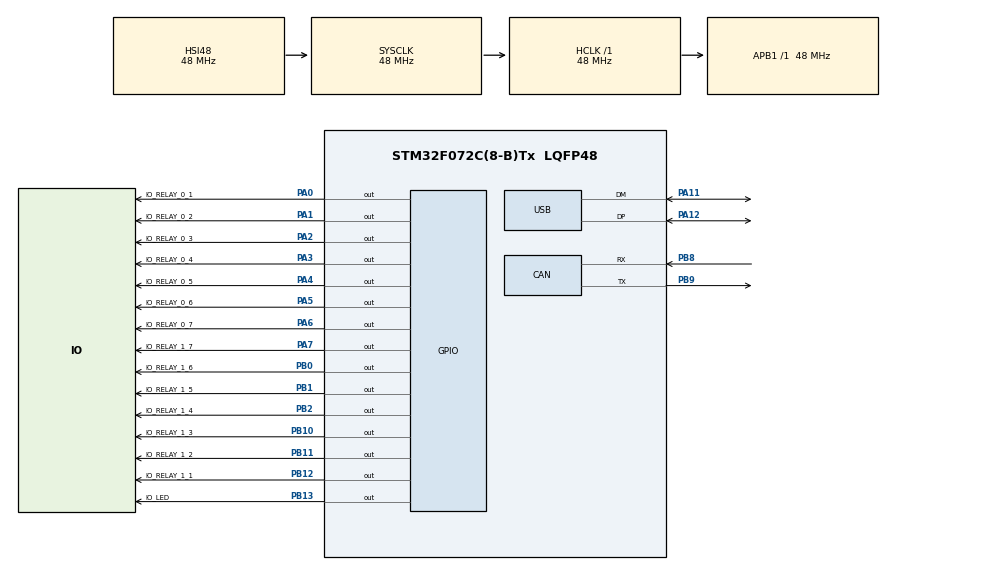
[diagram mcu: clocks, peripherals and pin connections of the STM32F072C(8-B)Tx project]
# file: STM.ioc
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CAN.CalculateTimeQuantum=333.3333333333333
FREERTOS.Queues01=cdcData,128,uint8_t,0,Dynamic,NULL,NULL
FREERTOS.Tasks01=ledToggleTask,-1,128,ledToggleTaskFunc,Default,NULL,Dynamic,NULL,NULL;uartTask,0,128,uartTaskFunc,Default,NULL,Dynamic,NULL,NULL
Mcu.Family=STM32F0
Mcu.Name=STM32F072C(8-B)Tx
Mcu.Package=LQFP48
NVIC.TIM1_BRK_UP_TRG_COM_IRQn=true\:0\:0\:false\:false\:true\:false\:false
NVIC.TimeBase=TIM1_BRK_UP_TRG_COM_IRQn
NVIC.TimeBaseIP=TIM1
NVIC.USB_IRQn=true\:3\:0\:false\:false\:true\:true\:false
PA0.GPIO_Label=IO_RELAY_0_1
PA0.Signal=GPIO_Output
PA1.GPIO_Label=IO_RELAY_0_2
PA1.Signal=GPIO_Output
PA11.Mode=Device
PA11.Signal=USB_DM
PA12.Mode=Device
PA12.Signal=USB_DP
PA2.GPIO_Label=IO_RELAY_0_3
PA2.Signal=GPIO_Output
PA3.GPIO_Label=IO_RELAY_0_4
PA3.Signal=GPIO_Output
PA4.GPIO_Label=IO_RELAY_0_5
PA4.Signal=GPIO_Output
PA5.GPIO_Label=IO_RELAY_0_6
PA5.Signal=GPIO_Output
PA6.GPIO_Label=IO_RELAY_0_7
PA6.Signal=GPIO_Output
PA7.GPIO_Label=IO_RELAY_1_7
PA7.Signal=GPIO_Output
PB0.GPIO_Label=IO_RELAY_1_6
PB0.Signal=GPIO_Output
PB1.GPIO_Label=IO_RELAY_1_5
PB1.Signal=GPIO_Output
PB10.GPIO_Label=IO_RELAY_1_3
PB10.Signal=GPIO_Output
PB11.GPIO_Label=IO_RELAY_1_2
PB11.Signal=GPIO_Output
PB12.GPIO_Label=IO_RELAY_1_1
PB12.Signal=GPIO_Output
PB13.GPIO_Label=IO_LED
PB13.Signal=GPIO_Output
PB2.GPIO_Label=IO_RELAY_1_4
PB2.Signal=GPIO_Output
PB3.Signal=SPI1_SCK
PB4.Signal=SPI1_MISO
PB5.Signal=SPI1_MOSI
PB8.Mode=Master
PB8.Signal=CAN_RX
PB9.Mode=Master
PB9.Signal=CAN_TX
ProjectManager.HeapSize=0x200
ProjectManager.StackSize=0x400
ProjectManager.TargetToolchain=TrueSTUDIO
RCC.AHBFreq_Value=48000000
RCC.APB1Freq_Value=48000000
RCC.APB1TimFreq_Value=48000000
RCC.HCLKFreq_Value=48000000
RCC.SYSCLKFreq_VALUE=48000000
RCC.SYSCLKSource=RCC_SYSCLKSOURCE_HSI48
USB_DEVICE.CLASS_NAME_FS=CDC
USB_DEVICE.VirtualMode=Cdc
USB_DEVICE.VirtualModeFS=Cdc_FS
VP_FREERTOS_VS_ENABLE.Mode=Enabled
VP_SYS_VS_tim1.Mode=TIM1
VP_USB_DEVICE_VS_USB_DEVICE_CDC_FS.Mode=CDC_FS
board=custom

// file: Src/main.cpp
/* USER CODE BEGIN Header */
/**
  ******************************************************************************
  * @file           : main.c
  * @brief          : Main program body
  ******************************************************************************
  ** This notice applies to any and all portions of this file
  * that are not between comment pairs USER CODE BEGIN and
  * USER CODE END. Other portions of this file, whether
  * inserted by the user or by software development tools
  * are owned by their respective copyright owners.
  *
  * COPYRIGHT(c) 2019 STMicroelectronics
  *
  * Redistribution and use in source and binary forms, with or without modification,
  * are permitted provided that the following conditions are met:
  *   1. Redistributions of source code must retain the above copyright notice,
  *      this list of conditions and the following disclaimer.
  *   2. Redistributions in binary form must reproduce the above copyright notice,
  *      this list of conditions and the following disclaimer in the documentation
  *      and/or other materials provided with the distribution.
  *   3. Neither the name of STMicroelectronics nor the names of its contributors
  *      may be used to endorse or promote products derived from this software
  *      without specific prior written permission.
  *
  * THIS SOFTWARE IS PROVIDED BY THE COPYRIGHT HOLDERS AND CONTRIBUTORS "AS IS"
  * AND ANY EXPRESS OR IMPLIED WARRANTIES, INCLUDING, BUT NOT LIMITED TO, THE
  * IMPLIED WARRANTIES OF MERCHANTABILITY AND FITNESS FOR A PARTICULAR PURPOSE ARE
  * DISCLAIMED. IN NO EVENT SHALL THE COPYRIGHT HOLDER OR CONTRIBUTORS BE LIABLE
  * FOR ANY DIRECT, INDIRECT, INCIDENTAL, SPECIAL, EXEMPLARY, OR CONSEQUENTIAL
  * DAMAGES (INCLUDING, BUT NOT LIMITED TO, PROCUREMENT OF SUBSTITUTE GOODS OR
  * SERVICES; LOSS OF USE, DATA, OR PROFITS; OR BUSINESS INTERRUPTION) HOWEVER
  * CAUSED AND ON ANY THEORY OF LIABILITY, WHETHER IN CONTRACT, STRICT LIABILITY,
  * OR TORT (INCLUDING NEGLIGENCE OR OTHERWISE) ARISING IN ANY WAY OUT OF THE USE
  * OF THIS SOFTWARE, EVEN IF ADVISED OF THE POSSIBILITY OF SUCH DAMAGE.
  *
  ******************************************************************************
  */
/* USER CODE END Header */

#include "main.h"
#include "cmsis_os.h"
#include "usb_device.h"

/* USER CODE BEGIN Includes */
#include "control.hpp"
/* USER CODE END Includes */

CAN_HandleTypeDef hcan;

osThreadId ledToggleTaskHandle;
osThreadId uartTaskHandle;
osMessageQId cdcDataHandle;

void SystemClock_Config(void);
static void MX_GPIO_Init(void);
static void MX_CAN_Init(void);
void ledToggleTaskFunc(void const * argument);
void uartTaskFunc(void const * argument);

int main(void)
{

  /* MCU Configuration--------------------------------------------------------*/

  /* Reset of all peripherals, Initializes the Flash interface and the Systick. */
  HAL_Init();

  /* Configure the system clock */
  SystemClock_Config();

  /* Initialize all configured peripherals */
  MX_GPIO_Init();
  MX_CAN_Init();

  /* Create the thread(s) */
  /* definition and creation of ledToggleTask */
  osThreadDef(ledToggleTask, ledToggleTaskFunc, osPriorityBelowNormal, 0, 128);
  ledToggleTaskHandle = osThreadCreate(osThread(ledToggleTask), NULL);

  /* definition and creation of uartTask */
  osThreadDef(uartTask, uartTaskFunc, osPriorityNormal, 0, 128);
  uartTaskHandle = osThreadCreate(osThread(uartTask), NULL);

  /* Create the queue(s) */
  /* definition and creation of cdcData */
  osMessageQDef(cdcData, 128, uint8_t);
  cdcDataHandle = osMessageCreate(osMessageQ(cdcData), NULL);

  /* Start scheduler */
  osKernelStart();

  /* We should never get here as control is now taken by the scheduler */

  /* Infinite loop */
  while (1)
  {

  }
}

void SystemClock_Config(void)
{
  RCC_OscInitTypeDef RCC_OscInitStruct = {0};
  RCC_ClkInitTypeDef RCC_ClkInitStruct = {0};
  RCC_PeriphCLKInitTypeDef PeriphClkInit = {0};

  /**Initializes the CPU, AHB and APB busses clocks
  */
  RCC_OscInitStruct.OscillatorType = RCC_OSCILLATORTYPE_HSI48;
  RCC_OscInitStruct.HSI48State = RCC_HSI48_ON;
  RCC_OscInitStruct.PLL.PLLState = RCC_PLL_NONE;
  if (HAL_RCC_OscConfig(&RCC_OscInitStruct) != HAL_OK)
  {
    Error_Handler();
  }
  /**Initializes the CPU, AHB and APB busses clocks
  */
  RCC_ClkInitStruct.ClockType = RCC_CLOCKTYPE_HCLK|RCC_CLOCKTYPE_SYSCLK
                              |RCC_CLOCKTYPE_PCLK1;
  RCC_ClkInitStruct.SYSCLKSource = RCC_SYSCLKSOURCE_HSI48;
  RCC_ClkInitStruct.AHBCLKDivider = RCC_SYSCLK_DIV1;
  RCC_ClkInitStruct.APB1CLKDivider = RCC_HCLK_DIV1;

  if (HAL_RCC_ClockConfig(&RCC_ClkInitStruct, FLASH_LATENCY_1) != HAL_OK)
  {
    Error_Handler();
  }
  PeriphClkInit.PeriphClockSelection = RCC_PERIPHCLK_USB;
  PeriphClkInit.UsbClockSelection = RCC_USBCLKSOURCE_HSI48;

  if (HAL_RCCEx_PeriphCLKConfig(&PeriphClkInit) != HAL_OK)
  {
    Error_Handler();
  }
}

static void MX_CAN_Init(void)
{

  hcan.Instance = CAN;
  hcan.Init.Prescaler = 16;
  hcan.Init.Mode = CAN_MODE_NORMAL;
  hcan.Init.SJW = CAN_SJW_1TQ;
  hcan.Init.BS1 = CAN_BS1_1TQ;
  hcan.Init.BS2 = CAN_BS2_1TQ;
  hcan.Init.TTCM = DISABLE;
  hcan.Init.ABOM = DISABLE;
  hcan.Init.AWUM = DISABLE;
  hcan.Init.NART = DISABLE;
  hcan.Init.RFLM = DISABLE;
  hcan.Init.TXFP = DISABLE;
  if (HAL_CAN_Init(&hcan) != HAL_OK)
  {
    Error_Handler();
  }

}

static void MX_GPIO_Init(void)
{
  GPIO_InitTypeDef GPIO_InitStruct = {0};

  /* GPIO Ports Clock Enable */
  __HAL_RCC_GPIOA_CLK_ENABLE();
  __HAL_RCC_GPIOB_CLK_ENABLE();

  /*Configure GPIO pin Output Level */
  HAL_GPIO_WritePin(GPIOA, IO_RELAY_0_1_Pin|IO_RELAY_0_2_Pin|IO_RELAY_0_3_Pin|IO_RELAY_0_4_Pin
                          |IO_RELAY_0_5_Pin|IO_RELAY_0_6_Pin|IO_RELAY_0_7_Pin|IO_RELAY_1_7_Pin, GPIO_PIN_RESET);

  /*Configure GPIO pin Output Level */
  HAL_GPIO_WritePin(GPIOB, IO_RELAY_1_6_Pin|IO_RELAY_1_5_Pin|IO_RELAY_1_4_Pin|IO_RELAY_1_3_Pin
                          |IO_RELAY_1_2_Pin|IO_RELAY_1_1_Pin|IO_LED_Pin, GPIO_PIN_RESET);

  /*Configure GPIO pins : IO_RELAY_0_1_Pin IO_RELAY_0_2_Pin IO_RELAY_0_3_Pin IO_RELAY_0_4_Pin
                           IO_RELAY_0_5_Pin IO_RELAY_0_6_Pin IO_RELAY_0_7_Pin IO_RELAY_1_7_Pin */
  GPIO_InitStruct.Pin = IO_RELAY_0_1_Pin|IO_RELAY_0_2_Pin|IO_RELAY_0_3_Pin|IO_RELAY_0_4_Pin
                          |IO_RELAY_0_5_Pin|IO_RELAY_0_6_Pin|IO_RELAY_0_7_Pin|IO_RELAY_1_7_Pin;
  GPIO_InitStruct.Mode = GPIO_MODE_OUTPUT_PP;
  GPIO_InitStruct.Pull = GPIO_NOPULL;
  GPIO_InitStruct.Speed = GPIO_SPEED_FREQ_LOW;
  HAL_GPIO_Init(GPIOA, &GPIO_InitStruct);

  /*Configure GPIO pins : IO_RELAY_1_6_Pin IO_RELAY_1_5_Pin IO_RELAY_1_4_Pin IO_RELAY_1_3_Pin
                           IO_RELAY_1_2_Pin IO_RELAY_1_1_Pin IO_LED_Pin */
  GPIO_InitStruct.Pin = IO_RELAY_1_6_Pin|IO_RELAY_1_5_Pin|IO_RELAY_1_4_Pin|IO_RELAY_1_3_Pin
                          |IO_RELAY_1_2_Pin|IO_RELAY_1_1_Pin|IO_LED_Pin;
  GPIO_InitStruct.Mode = GPIO_MODE_OUTPUT_PP;
  GPIO_InitStruct.Pull = GPIO_NOPULL;
  GPIO_InitStruct.Speed = GPIO_SPEED_FREQ_LOW;
  HAL_GPIO_Init(GPIOB, &GPIO_InitStruct);

  /*Configure GPIO pins : PB3 PB4 PB5 */
  GPIO_InitStruct.Pin = GPIO_PIN_3|GPIO_PIN_4|GPIO_PIN_5;
  GPIO_InitStruct.Mode = GPIO_MODE_AF_PP;
  GPIO_InitStruct.Pull = GPIO_NOPULL;
  GPIO_InitStruct.Speed = GPIO_SPEED_FREQ_HIGH;
  GPIO_InitStruct.Alternate = GPIO_AF0_SPI1;
  HAL_GPIO_Init(GPIOB, &GPIO_InitStruct);

}

void ledToggleTaskFunc(void const * argument)
{
  /* USER CODE BEGIN 5 */
  /* Infinite loop */
  for(;;)
  {
	HAL_GPIO_WritePin(GPIOB, GPIO_PIN_13, GPIO_PIN_SET); // OFF
	osDelay(800);
	HAL_GPIO_WritePin(GPIOB, GPIO_PIN_13, GPIO_PIN_RESET);  // ON
	osDelay(50);
	HAL_GPIO_WritePin(GPIOB, GPIO_PIN_13, GPIO_PIN_SET);  // OFF
	osDelay(100);
	HAL_GPIO_WritePin(GPIOB, GPIO_PIN_13, GPIO_PIN_RESET); // ON
	osDelay(50);

  }
  /* USER CODE END 5 */
}

void uartTaskFunc(void const * argument)
{
  /* init code for USB_DEVICE */
  MX_USB_DEVICE_Init();
  control controlDrv;

  /* USER CODE BEGIN uartTaskFunc */

  /* Infinite loop */
  for(;;)
  {
	controlDrv.cyclic();
    osDelay(10);
  }
  /* USER CODE END uartTaskFunc */
}

void HAL_TIM_PeriodElapsedCallback(TIM_HandleTypeDef *htim)
{
  if (htim->Instance == TIM1) {
    HAL_IncTick();
  }
}

void Error_Handler(void)
{
}

/************************ (C) COPYRIGHT STMicroelectronics *****END OF FILE****/
